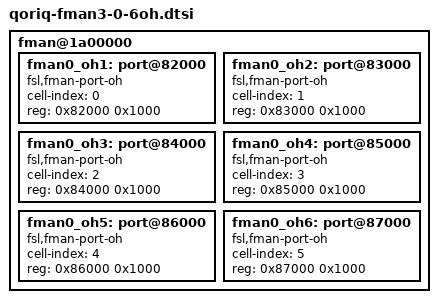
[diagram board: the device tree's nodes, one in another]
/*
 * QorIQ FMan v3 OH ports device tree
 *
 * Copyright 2012-2015 Freescale Semiconductor Inc.
 *
 * SPDX-License-Identifier: (GPL-2.0+ OR BSD-3-Clause)
 */

fman@1a00000 {

	fman0_oh1: port@82000 {
		cell-index = <0>;
		compatible = "fsl,fman-port-oh";
		reg = <0x82000 0x1000>;
	};

	fman0_oh2: port@83000 {
		cell-index = <1>;
		compatible = "fsl,fman-port-oh";
		reg = <0x83000 0x1000>;
	};

	fman0_oh3: port@84000 {
		cell-index = <2>;
		compatible = "fsl,fman-port-oh";
		reg = <0x84000 0x1000>;
	};

	fman0_oh4: port@85000 {
		cell-index = <3>;
		compatible = "fsl,fman-port-oh";
		reg = <0x85000 0x1000>;
	};

	fman0_oh5: port@86000 {
		cell-index = <4>;
		compatible = "fsl,fman-port-oh";
		reg = <0x86000 0x1000>;
	};

	fman0_oh6: port@87000 {
		cell-index = <5>;
		compatible = "fsl,fman-port-oh";
		reg = <0x87000 0x1000>;
	};

};
